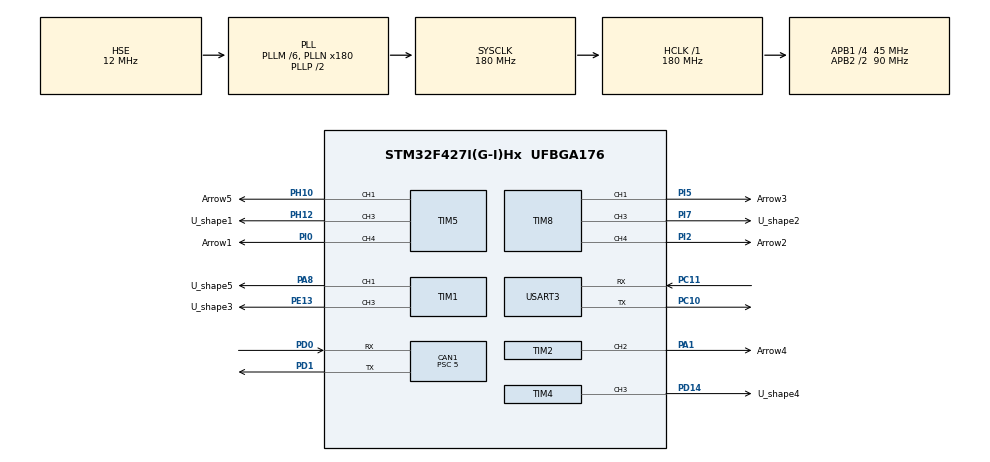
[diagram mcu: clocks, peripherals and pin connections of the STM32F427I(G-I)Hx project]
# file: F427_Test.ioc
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CAN1.BS1=CAN_BS1_3TQ
CAN1.BS2=CAN_BS2_5TQ
CAN1.CalculateBaudRate=1000000
CAN1.CalculateTimeBit=1000
CAN1.CalculateTimeQuantum=111.11111111111111
CAN1.NART=ENABLE
CAN1.Prescaler=5
Dma.Request0=TIM5_CH3/UP
Dma.Request1=TIM5_CH4/TRIG
Dma.Request10=USART3_RX
Dma.Request11=USART3_TX
Dma.Request2=TIM8_CH3
Dma.Request3=TIM8_CH4/TRIG/COM
Dma.Request4=TIM8_CH1
Dma.Request5=TIM2_CH2/CH4
Dma.Request6=TIM4_CH3
Dma.Request7=TIM5_CH1
Dma.Request8=TIM1_CH1
Dma.Request9=TIM1_CH3
Dma.TIM1_CH1.8.Direction=DMA_MEMORY_TO_PERIPH
Dma.TIM1_CH1.8.FIFOMode=DMA_FIFOMODE_DISABLE
Dma.TIM1_CH1.8.Instance=DMA2_Stream1
Dma.TIM1_CH1.8.MemDataAlignment=DMA_MDATAALIGN_HALFWORD
Dma.TIM1_CH1.8.MemInc=DMA_MINC_ENABLE
Dma.TIM1_CH1.8.Mode=DMA_CIRCULAR
Dma.TIM1_CH1.8.PeriphDataAlignment=DMA_PDATAALIGN_HALFWORD
Dma.TIM1_CH1.8.PeriphInc=DMA_PINC_DISABLE
Dma.TIM1_CH1.8.Priority=DMA_PRIORITY_HIGH
Dma.TIM1_CH3.9.Direction=DMA_MEMORY_TO_PERIPH
Dma.TIM1_CH3.9.FIFOMode=DMA_FIFOMODE_DISABLE
Dma.TIM1_CH3.9.Instance=DMA2_Stream6
Dma.TIM1_CH3.9.MemDataAlignment=DMA_MDATAALIGN_HALFWORD
Dma.TIM1_CH3.9.MemInc=DMA_MINC_ENABLE
Dma.TIM1_CH3.9.Mode=DMA_CIRCULAR
Dma.TIM1_CH3.9.PeriphDataAlignment=DMA_PDATAALIGN_HALFWORD
Dma.TIM1_CH3.9.PeriphInc=DMA_PINC_DISABLE
Dma.TIM1_CH3.9.Priority=DMA_PRIORITY_HIGH
Dma.TIM2_CH2/CH4.5.Direction=DMA_MEMORY_TO_PERIPH
Dma.TIM2_CH2/CH4.5.FIFOMode=DMA_FIFOMODE_DISABLE
Dma.TIM2_CH2/CH4.5.Instance=DMA1_Stream6
Dma.TIM2_CH2/CH4.5.MemDataAlignment=DMA_MDATAALIGN_WORD
Dma.TIM2_CH2/CH4.5.MemInc=DMA_MINC_ENABLE
Dma.TIM2_CH2/CH4.5.Mode=DMA_CIRCULAR
Dma.TIM2_CH2/CH4.5.PeriphDataAlignment=DMA_PDATAALIGN_WORD
Dma.TIM2_CH2/CH4.5.PeriphInc=DMA_PINC_DISABLE
Dma.TIM2_CH2/CH4.5.Priority=DMA_PRIORITY_HIGH
Dma.TIM4_CH3.6.Direction=DMA_MEMORY_TO_PERIPH
Dma.TIM4_CH3.6.FIFOMode=DMA_FIFOMODE_DISABLE
Dma.TIM4_CH3.6.Instance=DMA1_Stream7
Dma.TIM4_CH3.6.MemDataAlignment=DMA_MDATAALIGN_HALFWORD
Dma.TIM4_CH3.6.MemInc=DMA_MINC_ENABLE
Dma.TIM4_CH3.6.Mode=DMA_CIRCULAR
Dma.TIM4_CH3.6.PeriphDataAlignment=DMA_PDATAALIGN_HALFWORD
Dma.TIM4_CH3.6.PeriphInc=DMA_PINC_DISABLE
Dma.TIM4_CH3.6.Priority=DMA_PRIORITY_HIGH
Dma.TIM5_CH1.7.Direction=DMA_MEMORY_TO_PERIPH
Dma.TIM5_CH1.7.FIFOMode=DMA_FIFOMODE_DISABLE
Dma.TIM5_CH1.7.Instance=DMA1_Stream2
Dma.TIM5_CH1.7.MemDataAlignment=DMA_MDATAALIGN_WORD
Dma.TIM5_CH1.7.MemInc=DMA_MINC_ENABLE
Dma.TIM5_CH1.7.Mode=DMA_CIRCULAR
Dma.TIM5_CH1.7.PeriphDataAlignment=DMA_PDATAALIGN_WORD
Dma.TIM5_CH1.7.PeriphInc=DMA_PINC_DISABLE
Dma.TIM5_CH1.7.Priority=DMA_PRIORITY_HIGH
Dma.TIM5_CH3/UP.0.Direction=DMA_MEMORY_TO_PERIPH
Dma.TIM5_CH3/UP.0.FIFOMode=DMA_FIFOMODE_DISABLE
Dma.TIM5_CH3/UP.0.Instance=DMA1_Stream0
Dma.TIM5_CH3/UP.0.MemDataAlignment=DMA_MDATAALIGN_WORD
Dma.TIM5_CH3/UP.0.MemInc=DMA_MINC_ENABLE
Dma.TIM5_CH3/UP.0.Mode=DMA_CIRCULAR
Dma.TIM5_CH3/UP.0.PeriphDataAlignment=DMA_PDATAALIGN_WORD
Dma.TIM5_CH3/UP.0.PeriphInc=DMA_PINC_DISABLE
Dma.TIM5_CH3/UP.0.Priority=DMA_PRIORITY_HIGH
Dma.TIM5_CH4/TRIG.1.Direction=DMA_MEMORY_TO_PERIPH
Dma.TIM5_CH4/TRIG.1.FIFOMode=DMA_FIFOMODE_DISABLE
Dma.TIM5_CH4/TRIG.1.Instance=DMA1_Stream3
Dma.TIM5_CH4/TRIG.1.MemDataAlignment=DMA_MDATAALIGN_WORD
Dma.TIM5_CH4/TRIG.1.MemInc=DMA_MINC_ENABLE
Dma.TIM5_CH4/TRIG.1.Mode=DMA_CIRCULAR
Dma.TIM5_CH4/TRIG.1.PeriphDataAlignment=DMA_PDATAALIGN_WORD
Dma.TIM5_CH4/TRIG.1.PeriphInc=DMA_PINC_DISABLE
Dma.TIM5_CH4/TRIG.1.Priority=DMA_PRIORITY_HIGH
Dma.TIM8_CH1.4.Direction=DMA_MEMORY_TO_PERIPH
Dma.TIM8_CH1.4.FIFOMode=DMA_FIFOMODE_DISABLE
Dma.TIM8_CH1.4.Instance=DMA2_Stream2
Dma.TIM8_CH1.4.MemDataAlignment=DMA_MDATAALIGN_HALFWORD
Dma.TIM8_CH1.4.MemInc=DMA_MINC_ENABLE
Dma.TIM8_CH1.4.Mode=DMA_CIRCULAR
Dma.TIM8_CH1.4.PeriphDataAlignment=DMA_PDATAALIGN_HALFWORD
Dma.TIM8_CH1.4.PeriphInc=DMA_PINC_DISABLE
Dma.TIM8_CH1.4.Priority=DMA_PRIORITY_HIGH
Dma.TIM8_CH3.2.Direction=DMA_MEMORY_TO_PERIPH
Dma.TIM8_CH3.2.FIFOMode=DMA_FIFOMODE_DISABLE
Dma.TIM8_CH3.2.Instance=DMA2_Stream4
Dma.TIM8_CH3.2.MemDataAlignment=DMA_MDATAALIGN_HALFWORD
Dma.TIM8_CH3.2.MemInc=DMA_MINC_ENABLE
Dma.TIM8_CH3.2.Mode=DMA_CIRCULAR
Dma.TIM8_CH3.2.PeriphDataAlignment=DMA_PDATAALIGN_HALFWORD
Dma.TIM8_CH3.2.PeriphInc=DMA_PINC_DISABLE
Dma.TIM8_CH3.2.Priority=DMA_PRIORITY_HIGH
Dma.TIM8_CH4/TRIG/COM.3.Direction=DMA_MEMORY_TO_PERIPH
Dma.TIM8_CH4/TRIG/COM.3.FIFOMode=DMA_FIFOMODE_DISABLE
Dma.TIM8_CH4/TRIG/COM.3.Instance=DMA2_Stream7
Dma.TIM8_CH4/TRIG/COM.3.MemDataAlignment=DMA_MDATAALIGN_HALFWORD
Dma.TIM8_CH4/TRIG/COM.3.MemInc=DMA_MINC_ENABLE
Dma.TIM8_CH4/TRIG/COM.3.Mode=DMA_CIRCULAR
Dma.TIM8_CH4/TRIG/COM.3.PeriphDataAlignment=DMA_PDATAALIGN_HALFWORD
Dma.TIM8_CH4/TRIG/COM.3.PeriphInc=DMA_PINC_DISABLE
Dma.TIM8_CH4/TRIG/COM.3.Priority=DMA_PRIORITY_HIGH
Dma.USART3_RX.10.Direction=DMA_PERIPH_TO_MEMORY
Dma.USART3_RX.10.FIFOMode=DMA_FIFOMODE_DISABLE
Dma.USART3_RX.10.Instance=DMA1_Stream1
Dma.USART3_RX.10.MemDataAlignment=DMA_MDATAALIGN_BYTE
Dma.USART3_RX.10.MemInc=DMA_MINC_ENABLE
Dma.USART3_RX.10.Mode=DMA_NORMAL
Dma.USART3_RX.10.PeriphDataAlignment=DMA_PDATAALIGN_BYTE
Dma.USART3_RX.10.PeriphInc=DMA_PINC_DISABLE
Dma.USART3_RX.10.Priority=DMA_PRIORITY_HIGH
Dma.USART3_TX.11.Direction=DMA_MEMORY_TO_PERIPH
Dma.USART3_TX.11.FIFOMode=DMA_FIFOMODE_DISABLE
Dma.USART3_TX.11.Instance=DMA1_Stream4
Dma.USART3_TX.11.MemDataAlignment=DMA_MDATAALIGN_BYTE
Dma.USART3_TX.11.MemInc=DMA_MINC_ENABLE
Dma.USART3_TX.11.Mode=DMA_NORMAL
Dma.USART3_TX.11.PeriphDataAlignment=DMA_PDATAALIGN_BYTE
Dma.USART3_TX.11.PeriphInc=DMA_PINC_DISABLE
Dma.USART3_TX.11.Priority=DMA_PRIORITY_HIGH
FREERTOS.Tasks01=ArrowLED1,24,128,ArrowLED1_control,As weak,NULL,Dynamic,NULL,NULL;U_shapeLED1,24,128,U_shapeLED1_control,As weak,NULL,Dynamic,NULL,NULL;ArrowLED2,24,128,ArrowLED2_control,As weak,NULL,Dynamic,NULL,NULL;U_shapeLED2,24,128,U_shapeLED2_control,As weak,NULL,Dynamic,NULL,NULL;ArrowLED3,24,128,ArrowLED3_control,As weak,NULL,Dynamic,NULL,NULL;ArrowLED4,24,128,ArrowLED4_control,As weak,NULL,Dynamic,NULL,NULL;ArrowLED5,24,128,ArrowLED5_control,As weak,NULL,Dynamic,NULL,NULL;U_shapeLED3,24,128,U_shapeLED3_control,As weak,NULL,Dynamic,NULL,NULL;U_shapeLED4,24,128,U_shapeLED4_control,As weak,NULL,Dynamic,NULL,NULL;U_shapeLED5,24,128,U_shapeLED5_control,As weak,NULL,Dynamic,NULL,NULL;CAN_handle,24,128,CAN_handle_task,As weak,NULL,Dynamic,NULL,NULL;MainControl,24,128,MainControl_task,As weak,NULL,Dynamic,NULL,NULL
FREERTOS.configMINIMAL_STACK_SIZE=64
Mcu.Family=STM32F4
Mcu.Name=STM32F427I(G-I)Hx
Mcu.Package=UFBGA176
NVIC.CAN1_RX0_IRQn=true\:5\:0\:false\:false\:true\:true\:true\:true\:true
NVIC.CAN1_TX_IRQn=true\:5\:0\:false\:false\:true\:true\:true\:true\:true
NVIC.DMA1_Stream0_IRQn=true\:5\:0\:false\:false\:true\:true\:false\:true\:true
NVIC.DMA1_Stream1_IRQn=true\:5\:0\:false\:false\:true\:true\:false\:true\:true
NVIC.DMA1_Stream2_IRQn=true\:5\:0\:false\:false\:true\:true\:false\:true\:true
NVIC.DMA1_Stream3_IRQn=true\:5\:0\:false\:false\:true\:false\:false\:true\:true
NVIC.DMA1_Stream4_IRQn=true\:5\:0\:false\:false\:true\:true\:false\:true\:true
NVIC.DMA1_Stream6_IRQn=true\:5\:0\:false\:false\:true\:true\:false\:true\:true
NVIC.DMA1_Stream7_IRQn=true\:5\:0\:false\:false\:true\:true\:false\:true\:true
NVIC.DMA2_Stream1_IRQn=true\:5\:0\:false\:false\:true\:false\:false\:true\:true
NVIC.DMA2_Stream2_IRQn=true\:5\:0\:false\:false\:true\:true\:false\:true\:true
NVIC.DMA2_Stream4_IRQn=true\:5\:0\:false\:false\:true\:true\:false\:true\:true
NVIC.DMA2_Stream6_IRQn=true\:5\:0\:false\:false\:true\:true\:false\:true\:true
NVIC.DMA2_Stream7_IRQn=true\:5\:0\:false\:false\:true\:true\:false\:true\:true
NVIC.PriorityGroup=NVIC_PRIORITYGROUP_4
NVIC.TIM6_DAC_IRQn=true\:5\:0\:false\:false\:true\:true\:true\:true\:true
NVIC.TIM8_TRG_COM_TIM14_IRQn=true\:5\:0\:false\:false\:true\:false\:false\:true\:true
NVIC.TimeBase=TIM8_TRG_COM_TIM14_IRQn
NVIC.TimeBaseIP=TIM14
PA1.GPIO_Label=Arrow4
PA1.GPIO_PuPd=GPIO_PULLUP
PA1.GPIO_Speed=GPIO_SPEED_FREQ_LOW
PA1.Signal=S_TIM2_CH2
PA13.Mode=Serial_Wire
PA13.Signal=SYS_JTMS-SWDIO
PA14.Mode=Serial_Wire
PA14.Signal=SYS_JTCK-SWCLK
PA8.GPIO_Label=U_shape5
PA8.GPIO_PuPd=GPIO_PULLUP
PA8.GPIO_Speed=GPIO_SPEED_FREQ_LOW
PA8.Signal=S_TIM1_CH1
PC10.Mode=Asynchronous
PC10.Signal=USART3_TX
PC11.Mode=Asynchronous
PC11.Signal=USART3_RX
PD0.Mode=CAN_Activate
PD0.Signal=CAN1_RX
PD1.Mode=CAN_Activate
PD1.Signal=CAN1_TX
PD14.GPIO_Label=U_shape4
PD14.GPIO_PuPd=GPIO_PULLUP
PD14.GPIO_Speed=GPIO_SPEED_FREQ_LOW
PD14.Signal=S_TIM4_CH3
PE13.GPIO_Label=U_shape3
PE13.GPIO_PuPd=GPIO_PULLUP
PE13.GPIO_Speed=GPIO_SPEED_FREQ_LOW
PE13.Signal=S_TIM1_CH3
PH0/OSC_IN.Mode=HSE-External-Oscillator
PH0/OSC_IN.Signal=RCC_OSC_IN
PH1/OSC_OUT.Mode=HSE-External-Oscillator
PH1/OSC_OUT.Signal=RCC_OSC_OUT
PH10.GPIO_Label=Arrow5
PH10.GPIO_PuPd=GPIO_PULLUP
PH10.GPIO_Speed=GPIO_SPEED_FREQ_LOW
PH10.Signal=S_TIM5_CH1
PH12.GPIO_Label=U_shape1
PH12.GPIO_PuPd=GPIO_PULLUP
PH12.GPIO_Speed=GPIO_SPEED_FREQ_LOW
PH12.Signal=S_TIM5_CH3
PI0.GPIO_Label=Arrow1
PI0.GPIO_PuPd=GPIO_PULLUP
PI0.GPIO_Speed=GPIO_SPEED_FREQ_LOW
PI0.Signal=S_TIM5_CH4
PI2.GPIO_Label=Arrow2
PI2.GPIO_PuPd=GPIO_PULLUP
PI2.GPIO_Speed=GPIO_SPEED_FREQ_LOW
PI2.Signal=S_TIM8_CH4
PI5.GPIO_Label=Arrow3
PI5.GPIO_PuPd=GPIO_PULLUP
PI5.GPIO_Speed=GPIO_SPEED_FREQ_LOW
PI5.Signal=S_TIM8_CH1
PI7.GPIO_Label=U_shape2
PI7.GPIO_PuPd=GPIO_PULLUP
PI7.GPIO_Speed=GPIO_SPEED_FREQ_LOW
PI7.Signal=S_TIM8_CH3
ProjectManager.HeapSize=0x1200
ProjectManager.StackSize=0x800
ProjectManager.TargetToolchain=MDK-ARM V5.32
RCC.48MHZClocksFreq_Value=45000000
RCC.AHBFreq_Value=180000000
RCC.APB1CLKDivider=RCC_HCLK_DIV4
RCC.APB1Freq_Value=45000000
RCC.APB1TimFreq_Value=90000000
RCC.APB2CLKDivider=RCC_HCLK_DIV2
RCC.APB2Freq_Value=90000000
RCC.APB2TimFreq_Value=180000000
RCC.CortexFreq_Value=180000000
RCC.HCLKFreq_Value=180000000
RCC.HSE_VALUE=12000000
RCC.HSI_VALUE=16000000
RCC.LSE_VALUE=32768
RCC.PLLM=6
RCC.PLLN=180
RCC.PLLQ=8
RCC.PLLSourceVirtual=RCC_PLLSOURCE_HSE
RCC.SYSCLKFreq_VALUE=180000000
RCC.SYSCLKSource=RCC_SYSCLKSOURCE_PLLCLK
RCC.VCOOutputFreq_Value=360000000
SH.S_TIM1_CH1.0=TIM1_CH1,PWM Generation1 CH1
SH.S_TIM1_CH3.0=TIM1_CH3,PWM Generation3 CH3
SH.S_TIM2_CH2.0=TIM2_CH2,PWM Generation2 CH2
SH.S_TIM4_CH3.0=TIM4_CH3,PWM Generation3 CH3
SH.S_TIM5_CH1.0=TIM5_CH1,PWM Generation1 CH1
SH.S_TIM5_CH3.0=TIM5_CH3,PWM Generation3 CH3
SH.S_TIM5_CH4.0=TIM5_CH4,PWM Generation4 CH4
SH.S_TIM8_CH1.0=TIM8_CH1,PWM Generation1 CH1
SH.S_TIM8_CH3.0=TIM8_CH3,PWM Generation3 CH3
SH.S_TIM8_CH4.0=TIM8_CH4,PWM Generation4 CH4
STMicroelectronics.X-CUBE-AI.8.0.0.HeapSize=0x1200
STMicroelectronics.X-CUBE-AI.8.0.0.ReadyForCodeGeneration=false
STMicroelectronics.X-CUBE-AI.8.0.0.StackSize=0x800
TIM1.Channel-PWM\ Generation1\ CH1=TIM_CHANNEL_1
TIM1.Channel-PWM\ Generation3\ CH3=TIM_CHANNEL_3
TIM2.Channel-PWM\ Generation2\ CH2=TIM_CHANNEL_2
TIM4.Channel-PWM\ Generation3\ CH3=TIM_CHANNEL_3
TIM5.Channel-PWM\ Generation1\ CH1=TIM_CHANNEL_1
TIM5.Channel-PWM\ Generation3\ CH3=TIM_CHANNEL_3
TIM5.Channel-PWM\ Generation4\ CH4=TIM_CHANNEL_4
TIM6.Period=1000-1
TIM6.Prescaler=90-1
TIM8.Channel-PWM\ Generation1\ CH1=TIM_CHANNEL_1
TIM8.Channel-PWM\ Generation3\ CH3=TIM_CHANNEL_3
TIM8.Channel-PWM\ Generation4\ CH4=TIM_CHANNEL_4
USART3.VirtualMode=VM_ASYNC
VP_CRC_VS_CRC.Mode=CRC_Activate
VP_FREERTOS_VS_CMSIS_V2.Mode=CMSIS_V2
VP_RNG_VS_RNG.Mode=RNG_Activate
VP_SYS_VS_tim14.Mode=TIM14
VP_TIM1_VS_ClockSourceINT.Mode=Internal
VP_TIM2_VS_ClockSourceINT.Mode=Internal
VP_TIM5_VS_ClockSourceINT.Mode=Internal
VP_TIM6_VS_ClockSourceINT.Mode=Enable_Timer
VP_TIM8_VS_ClockSourceINT.Mode=Internal
board=custom

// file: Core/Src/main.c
/* USER CODE BEGIN Header */
/**
 ******************************************************************************
 * @file           : main.c
 * @brief          : Main program body
 ******************************************************************************
 * @attention
 *
 * Copyright (c) 2023 STMicroelectronics.
 * All rights reserved.
 *
 * This software is licensed under terms that can be found in the LICENSE file
 * in the root directory of this software component.
 * If no LICENSE file comes with this software, it is provided AS-IS.
 *
 ******************************************************************************
 */
/* USER CODE END Header */
#include "main.h"
#include "cmsis_os.h"
#include "can.h"
#include "crc.h"
#include "dma.h"
#include "rng.h"
#include "tim.h"
#include "usart.h"
#include "gpio.h"

void SystemClock_Config(void);
void MX_FREERTOS_Init(void);

int main(void)
{

  /* MCU Configuration--------------------------------------------------------*/

  /* Reset of all peripherals, Initializes the Flash interface and the Systick. */
  HAL_Init();

  /* Configure the system clock */
  SystemClock_Config();

  /* Initialize all configured peripherals */
  MX_GPIO_Init();
  MX_DMA_Init();
  MX_TIM5_Init();
  MX_TIM8_Init();
  MX_TIM2_Init();
  MX_TIM4_Init();
  MX_TIM1_Init();
  MX_USART3_UART_Init();
  MX_CAN1_Init();
  MX_RNG_Init();
  MX_TIM6_Init();
  MX_CRC_Init();
  /* USER CODE BEGIN 2 */
  HAL_TIM_Base_Start(&htim6);
  HAL_CAN_Start(&hcan1);
  /* USER CODE END 2 */

  /* Init scheduler */
  osKernelInitialize(); /* Call init function for freertos objects (in freertos.c) */
  MX_FREERTOS_Init();

  /* Start scheduler */
  osKernelStart();
  /* We should never get here as control is now taken by the scheduler */
  /* Infinite loop */
  while (1)
  {

  }
}

void SystemClock_Config(void)
{
  RCC_OscInitTypeDef RCC_OscInitStruct = {0};
  RCC_ClkInitTypeDef RCC_ClkInitStruct = {0};

  /** Configure the main internal regulator output voltage
   */
  __HAL_RCC_PWR_CLK_ENABLE();
  __HAL_PWR_VOLTAGESCALING_CONFIG(PWR_REGULATOR_VOLTAGE_SCALE1);

  /** Initializes the RCC Oscillators according to the specified parameters
   * in the RCC_OscInitTypeDef structure.
   */
  RCC_OscInitStruct.OscillatorType = RCC_OSCILLATORTYPE_HSE;
  RCC_OscInitStruct.HSEState = RCC_HSE_ON;
  RCC_OscInitStruct.PLL.PLLState = RCC_PLL_ON;
  RCC_OscInitStruct.PLL.PLLSource = RCC_PLLSOURCE_HSE;
  RCC_OscInitStruct.PLL.PLLM = 6;
  RCC_OscInitStruct.PLL.PLLN = 180;
  RCC_OscInitStruct.PLL.PLLP = RCC_PLLP_DIV2;
  RCC_OscInitStruct.PLL.PLLQ = 8;
  if (HAL_RCC_OscConfig(&RCC_OscInitStruct) != HAL_OK)
  {
    Error_Handler();
  }

  /** Activate the Over-Drive mode
   */
  if (HAL_PWREx_EnableOverDrive() != HAL_OK)
  {
    Error_Handler();
  }

  /** Initializes the CPU, AHB and APB buses clocks
   */
  RCC_ClkInitStruct.ClockType = RCC_CLOCKTYPE_HCLK | RCC_CLOCKTYPE_SYSCLK | RCC_CLOCKTYPE_PCLK1 | RCC_CLOCKTYPE_PCLK2;
  RCC_ClkInitStruct.SYSCLKSource = RCC_SYSCLKSOURCE_PLLCLK;
  RCC_ClkInitStruct.AHBCLKDivider = RCC_SYSCLK_DIV1;
  RCC_ClkInitStruct.APB1CLKDivider = RCC_HCLK_DIV4;
  RCC_ClkInitStruct.APB2CLKDivider = RCC_HCLK_DIV2;

  if (HAL_RCC_ClockConfig(&RCC_ClkInitStruct, FLASH_LATENCY_5) != HAL_OK)
  {
    Error_Handler();
  }
}

void HAL_TIM_PeriodElapsedCallback(TIM_HandleTypeDef *htim)
{
  if (htim->Instance == TIM14)
  {
	  HAL_IncTick();
	  TIM6_tick++;
  }
  /* USER CODE BEGIN Callback 1 */
  // HAL_TIM_PeriodElapsedCallback_User1(htim);
  if (htim->Instance == TIM6)
  {

  }
  /* USER CODE END Callback 1 */
}

void Error_Handler(void)
{
  __disable_irq();
  while (1)
  {
  }
}

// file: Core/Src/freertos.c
/* USER CODE BEGIN Header */
/**
  ******************************************************************************
  * File Name          : freertos.c
  * Description        : Code for freertos applications
  ******************************************************************************
  * @attention
  *
  * Copyright (c) 2023 STMicroelectronics.
  * All rights reserved.
  *
  * This software is licensed under terms that can be found in the LICENSE file
  * in the root directory of this software component.
  * If no LICENSE file comes with this software, it is provided AS-IS.
  *
  ******************************************************************************
  */
/* USER CODE END Header */

#include "FreeRTOS.h"
#include "task.h"
#include "main.h"
#include "cmsis_os.h"

/* Definitions for ArrowLED1 */
osThreadId_t ArrowLED1Handle;
const osThreadAttr_t ArrowLED1_attributes = {
  .name = "ArrowLED1",
  .stack_size = 128 * 4,
  .priority = (osPriority_t) osPriorityNormal,
};
/* Definitions for U_shapeLED1 */
osThreadId_t U_shapeLED1Handle;
const osThreadAttr_t U_shapeLED1_attributes = {
  .name = "U_shapeLED1",
  .stack_size = 128 * 4,
  .priority = (osPriority_t) osPriorityNormal,
};
/* Definitions for ArrowLED2 */
osThreadId_t ArrowLED2Handle;
const osThreadAttr_t ArrowLED2_attributes = {
  .name = "ArrowLED2",
  .stack_size = 128 * 4,
  .priority = (osPriority_t) osPriorityNormal,
};
/* Definitions for U_shapeLED2 */
osThreadId_t U_shapeLED2Handle;
const osThreadAttr_t U_shapeLED2_attributes = {
  .name = "U_shapeLED2",
  .stack_size = 128 * 4,
  .priority = (osPriority_t) osPriorityNormal,
};
/* Definitions for ArrowLED3 */
osThreadId_t ArrowLED3Handle;
const osThreadAttr_t ArrowLED3_attributes = {
  .name = "ArrowLED3",
  .stack_size = 128 * 4,
  .priority = (osPriority_t) osPriorityNormal,
};
/* Definitions for ArrowLED4 */
osThreadId_t ArrowLED4Handle;
const osThreadAttr_t ArrowLED4_attributes = {
  .name = "ArrowLED4",
  .stack_size = 128 * 4,
  .priority = (osPriority_t) osPriorityNormal,
};
/* Definitions for ArrowLED5 */
osThreadId_t ArrowLED5Handle;
const osThreadAttr_t ArrowLED5_attributes = {
  .name = "ArrowLED5",
  .stack_size = 128 * 4,
  .priority = (osPriority_t) osPriorityNormal,
};
/* Definitions for U_shapeLED3 */
osThreadId_t U_shapeLED3Handle;
const osThreadAttr_t U_shapeLED3_attributes = {
  .name = "U_shapeLED3",
  .stack_size = 128 * 4,
  .priority = (osPriority_t) osPriorityNormal,
};
/* Definitions for U_shapeLED4 */
osThreadId_t U_shapeLED4Handle;
const osThreadAttr_t U_shapeLED4_attributes = {
  .name = "U_shapeLED4",
  .stack_size = 128 * 4,
  .priority = (osPriority_t) osPriorityNormal,
};
/* Definitions for U_shapeLED5 */
osThreadId_t U_shapeLED5Handle;
const osThreadAttr_t U_shapeLED5_attributes = {
  .name = "U_shapeLED5",
  .stack_size = 128 * 4,
  .priority = (osPriority_t) osPriorityNormal,
};
/* Definitions for CAN_handle */
osThreadId_t CAN_handleHandle;
const osThreadAttr_t CAN_handle_attributes = {
  .name = "CAN_handle",
  .stack_size = 128 * 4,
  .priority = (osPriority_t) osPriorityNormal,
};
/* Definitions for MainControl */
osThreadId_t MainControlHandle;
const osThreadAttr_t MainControl_attributes = {
  .name = "MainControl",
  .stack_size = 128 * 4,
  .priority = (osPriority_t) osPriorityNormal,
};

void ArrowLED1_control(void *argument);
void U_shapeLED1_control(void *argument);
void ArrowLED2_control(void *argument);
void U_shapeLED2_control(void *argument);
void ArrowLED3_control(void *argument);
void ArrowLED4_control(void *argument);
void ArrowLED5_control(void *argument);
void U_shapeLED3_control(void *argument);
void U_shapeLED4_control(void *argument);
void U_shapeLED5_control(void *argument);
void CAN_handle_task(void *argument);
void MainControl_task(void *argument);

void MX_FREERTOS_Init(void); /* (MISRA C 2004 rule 8.1) */

void MX_FREERTOS_Init(void) {

  /* Create the thread(s) */
  /* creation of ArrowLED1 */
  ArrowLED1Handle = osThreadNew(ArrowLED1_control, NULL, &ArrowLED1_attributes);

  /* creation of U_shapeLED1 */
  U_shapeLED1Handle = osThreadNew(U_shapeLED1_control, NULL, &U_shapeLED1_attributes);

  /* creation of ArrowLED2 */
  ArrowLED2Handle = osThreadNew(ArrowLED2_control, NULL, &ArrowLED2_attributes);

  /* creation of U_shapeLED2 */
  U_shapeLED2Handle = osThreadNew(U_shapeLED2_control, NULL, &U_shapeLED2_attributes);

  /* creation of ArrowLED3 */
  ArrowLED3Handle = osThreadNew(ArrowLED3_control, NULL, &ArrowLED3_attributes);

  /* creation of ArrowLED4 */
  ArrowLED4Handle = osThreadNew(ArrowLED4_control, NULL, &ArrowLED4_attributes);

  /* creation of ArrowLED5 */
  ArrowLED5Handle = osThreadNew(ArrowLED5_control, NULL, &ArrowLED5_attributes);

  /* creation of U_shapeLED3 */
  U_shapeLED3Handle = osThreadNew(U_shapeLED3_control, NULL, &U_shapeLED3_attributes);

  /* creation of U_shapeLED4 */
  U_shapeLED4Handle = osThreadNew(U_shapeLED4_control, NULL, &U_shapeLED4_attributes);

  /* creation of U_shapeLED5 */
  U_shapeLED5Handle = osThreadNew(U_shapeLED5_control, NULL, &U_shapeLED5_attributes);

  /* creation of CAN_handle */
  CAN_handleHandle = osThreadNew(CAN_handle_task, NULL, &CAN_handle_attributes);

  /* creation of MainControl */
  MainControlHandle = osThreadNew(MainControl_task, NULL, &MainControl_attributes);

}

__weak void ArrowLED1_control(void *argument)
{
  for(;;)
  {
    osDelay(1);
  }
}

__weak void U_shapeLED1_control(void *argument)
{
  for(;;)
  {
    osDelay(1);
  }
}

__weak void ArrowLED2_control(void *argument)
{
  for(;;)
  {
    osDelay(1);
  }
}

__weak void U_shapeLED2_control(void *argument)
{
  for(;;)
  {
    osDelay(1);
  }
}

__weak void ArrowLED3_control(void *argument)
{
  for(;;)
  {
    osDelay(1);
  }
}

__weak void ArrowLED4_control(void *argument)
{
  for(;;)
  {
    osDelay(1);
  }
}

__weak void ArrowLED5_control(void *argument)
{
  for(;;)
  {
    osDelay(1);
  }
}

__weak void U_shapeLED3_control(void *argument)
{
  for(;;)
  {
    osDelay(1);
  }
}

__weak void U_shapeLED4_control(void *argument)
{
  for(;;)
  {
    osDelay(1);
  }
}

__weak void U_shapeLED5_control(void *argument)
{
  for(;;)
  {
    osDelay(1);
  }
}

__weak void CAN_handle_task(void *argument)
{
  for(;;)
  {
    osDelay(1);
  }
}

__weak void MainControl_task(void *argument)
{
  for(;;)
  {
    osDelay(1);
  }
}
